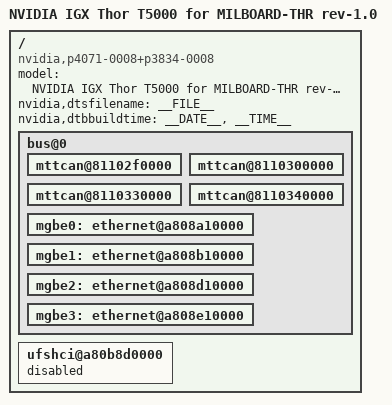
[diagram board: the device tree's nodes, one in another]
// SPDX-License-Identifier: GPL-2.0-only
// SPDX-FileCopyrightText: Copyright (c) 2025-2026, NVIDIA CORPORATION & AFFILIATES.  All rights reserved.
/dts-v1/;

#include "tegra264-p4071-0000+p3834-0008-nv-milboard-thr-base-rev10.dts"

/ {
	model = "NVIDIA IGX Thor T5000 for MILBOARD-THR rev-1.0";
	compatible = "nvidia,p4071-0008+p3834-0008", "nvidia,p3834-0008", "nvidia,tegra264";
	nvidia,dtsfilename = __FILE__;
	nvidia,dtbbuildtime = __DATE__, __TIME__;

	bus@0 {
		mttcan@81102f0000 {
			status = "okay";
		};

		mttcan@8110300000 {
			status = "okay";
		};

		mttcan@8110330000 {
			status = "okay";
                };

		mttcan@8110340000 {
			status = "okay";
		};

		mgbe0: ethernet@a808a10000 {
			status = "okay";
		};

		mgbe1: ethernet@a808b10000 {
			status = "okay";
		};

		mgbe2: ethernet@a808d10000 {
			status = "okay";
		};

		mgbe3: ethernet@a808e10000 {
			status = "okay";
		};
	};

	ufshci@a80b8d0000 {
		status = "disabled";
	};
};
